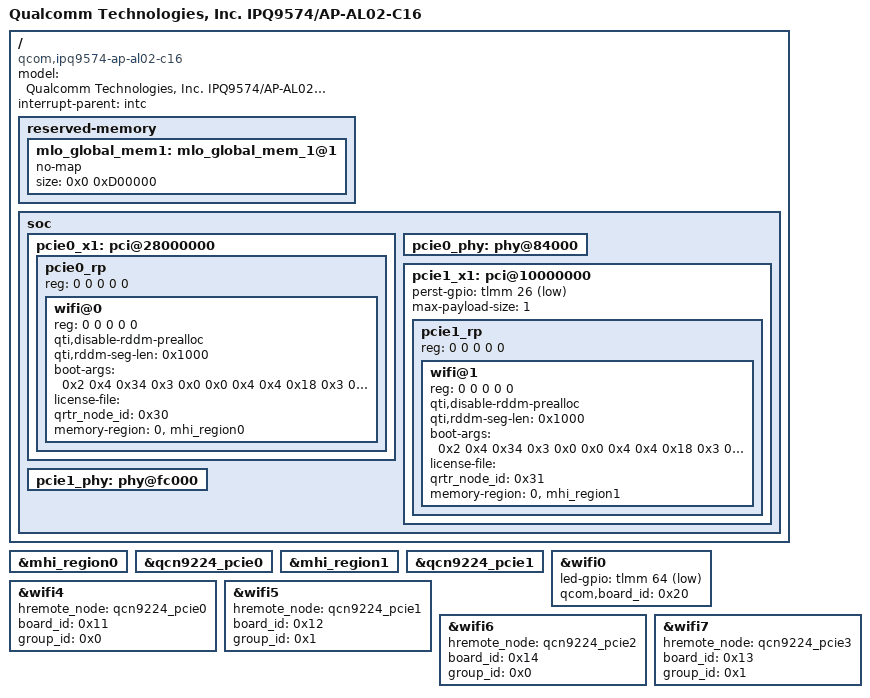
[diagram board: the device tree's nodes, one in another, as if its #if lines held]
// SPDX-License-Identifier: (GPL-2.0+ OR BSD-3-Clause)
/*
 * IPQ9574 AL02-C16 board device tree source
 *
 * Copyright (c) 2020-2021 The Linux Foundation. All rights reserved.
 * Copyright (c) 2022 Qualcomm Innovation Center, Inc. All rights reserved.
 */

/dts-v1/;

#include "ipq9574-al02-c6.dts"

/ {
	#address-cells = <0x2>;
	#size-cells = <0x2>;
	model = "Qualcomm Technologies, Inc. IPQ9574/AP-AL02-C16";
	compatible = "qcom,ipq9574-ap-al02-c16", "qcom,ipq9574-al02", "qcom,ipq9574";
	interrupt-parent = <&intc>;

	reserved-memory {
		mlo_global_mem1: mlo_global_mem_1@1 {
			no-map;
			size = <0x0 0xD00000>;
			status = "ok";
		};
	};

	soc {
		pcie0_x1: pci@28000000 {
                        status = "ok";
                        pcie0_rp {
                                reg = <0 0 0 0 0>;

                                wifi@0 {
                                        reg = <0 0 0 0 0>;

					qti,disable-rddm-prealloc;
					qti,rddm-seg-len = <0x1000>;
					boot-args = <0x2 0x4 0x34 0x3 0x0 0x0     /* MX Rail, GPIO52, Drive strength 0x3 */
							0x4 0x4 0x18 0x3 0x0 0x0  /* RFA1p2 Rail, GPIO24, Drive strength 0x3 */
							0x0 0x4 0x0 0x0 0x0 0x0>; /* End of arguments */
					license-file = "";
#if defined(__CNSS2__)
                                        qrtr_node_id = <0x30>;
                                        memory-region = <0>,<&mhi_region0>;
#endif
                                };
                        };
                };

                pcie0_phy: phy@84000 {
                        status = "ok";
                };

		pcie1_x1: pci@10000000 {
			perst-gpio = <&tlmm 26 1>;
			max-payload-size = <1>; // 1-256 TLP bytes for WKK
			status = "ok";
			pcie1_rp {
				reg = <0 0 0 0 0>;

				wifi@1 {
					reg = <0 0 0 0 0>;

					qti,disable-rddm-prealloc;
					qti,rddm-seg-len = <0x1000>;
					boot-args = <0x2 0x4 0x34 0x3 0x0 0x0     /* MX Rail, GPIO52, Drive strength 0x3 */
							0x4 0x4 0x18 0x3 0x0 0x0  /* RFA1p2 Rail, GPIO24, Drive strength 0x3 */
							0x0 0x4 0x0 0x0 0x0 0x0>; /* End of arguments */
					license-file = "";
#if defined(__CNSS2__)
					qrtr_node_id = <0x31>;
					memory-region = <0>,<&mhi_region1>;
#endif
				};
			};
		};

		pcie1_phy: phy@fc000 {
			status = "ok";
		};

	};
};

&mhi_region0 {
	status = "ok";
};

&qcn9224_pcie0 {
	status = "ok";
};

&mhi_region1 {
	status = "ok";
};
&qcn9224_pcie1 {
	status = "ok";
};

&wifi0 {
	led-gpio = <&tlmm 64 1>;
        qcom,board_id = <0x20>;
        status = "ok";
};
&wifi4 {
	hremote_node = <&qcn9224_pcie0>;
        board_id = <0x11>;
        group_id = <0x0>;
	/delete-property/ interrupt-bmap;
        status = "ok";
};

&wifi5 {
	hremote_node = <&qcn9224_pcie1>;
        board_id = <0x12>;
        group_id = <0x1>;
	/delete-property/ interrupt-bmap;
        status = "ok";
};

&wifi6 {
	hremote_node = <&qcn9224_pcie2>;
        board_id = <0x14>;
        group_id = <0x0>;
        status = "ok";
};

&wifi7 {
	hremote_node = <&qcn9224_pcie3>;
        board_id = <0x13>;
        group_id = <0x1>;
        status = "ok";
};

